# MDR1986VE9x register map
Vendor: Milandr; Series: ARMCM3; File version: 2.0
CPU: CM3 r2p1, little endian, no MPU, no FPU, 3 interrupt priority bits
Registers are 32-bit, read-write, reset 0x0 unless marked. A register's access mark holds for its fields unless they carry their own. Offsets are from the block's base; [hi:lo] are bit positions.

## MDR_I2C — I2C Controler
Base 0x40050000
0x00 PRL — BitRate Div[7:0] of HCLK
  [7:0] PRL — Div[7:0] of HCLK
0x04 PRH — BitRate Div[15:8] of HCLK
  [7:0] PRH — Div[15:8] of HCLK
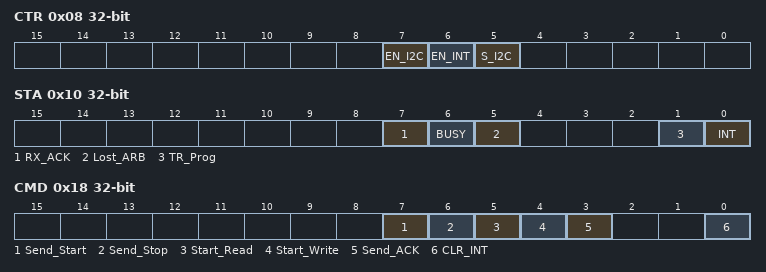
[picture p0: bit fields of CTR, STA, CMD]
0x08 CTR — Control Register
  [7] EN_I2C — Enable
    0=Off (Disabled); 1=On (Enabled)
  [6] EN_INT — Enable IRQ
    0=Off (Disabled); 1=On (Enabled)
  [5] S_I2C — Speed range of I2C
    0=less_400KHz (BitRate is less 400KHz); 1=less_1MHz (BitRate is less 1MHz)
0x0C RXD — Received Data
  [7:0] DATA — Received Byte
0x10 STA — Status register
  [7] RX_ACK — ACK Status
    0=Ok (Acknowledge received); 1=No Acknowledge received
  [6] BUSY — Line Busy
    0=Bus_Free (Stop received); 1=Bus_Busy (Start received)
  [5] Lost_ARB — Lost arbitrage
    0=Ok (Normal operation); 1=Collision detected
  [1] TR_Prog — Transfering status
    0=Completed (Transfering is completed); 1=Transfering is not completed
  [0] INT — IRQ Event Flag
    0=Off (Inactive); 1=On (Active)
0x14 TXD — Data to Send
  [7:0] DATA — Send Byte
0x18 CMD — Command Register
  [7] Send_Start — Send Start command
    0=Inactive state; 1=Send Start command
  [6] Send_Stop — Send Stop command
    0=Inactive state; 1=Send Stop command
  [5] Start_Read — Start Reading transfer
    0=Inactive state; 1=Start reading
  [4] Start_Write — Start Writing transfer
    0=Inactive state; 1=Start_Write (Start writing)
  [3] Send_ACK — Send ACK command
    0=Inactive state; 1=Send Ack command
  [0] CLR_INT — Clear IRQ Event
    0=Inactive state; 1=Clear IRQ flag

## MDR_Power — Power Detector
Base 0x40058000
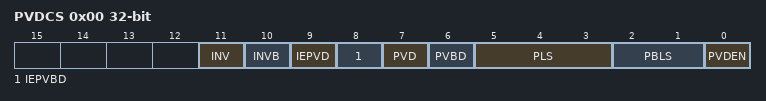
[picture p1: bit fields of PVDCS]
0x00 PVDCS — Control-Status register
  [11] INV — PVD event on BUcc lt PBLS
    0=Off (Disabled); 1=On (Enabled)
  [10] INVB — PVBD event on BUcc lt PBLS
    0=Off (Disabled); 1=On (Enabled)
  [9] IEPVD — Enable IRQ by PVD event
    0=Off (Disabled); 1=On (Enabled)
  [8] IEPVBD — Enable IRQ by PVBD event
    0=Off (Disabled); 1=On (Enabled)
  [7] PVD — Event on Ucc gt PLS
    0=Inactive (No Event); 1=Active (Event is active)
  [6] PVBD — Event on BUcc gt PBLS
    0=Inactive (No Event); 1=Active (Event is active)
  [5:3] PLS — Ucc compare level
    0=2v0 (Level of 2.0 volts); 1=2v2 (Level of 2.2 volts); 2=2v4 (Level of 2.4 volts); 3=2v6 (Level of 2.6 volts); 4=2v8 (Level of 2.8 volts); 5=3v0 (Level of 3.0 volts); 6=3v2 (Level of 3.2 volts); 7=3v4 (Level of 3.4 volts)
  [2:1] PBLS — BUcc compare level
    0=1v8 (Level of 1.8 volts); 1=2v2 (Level of 2.2 volts); 2=2v6 (Level of 2.6 volts); 3=3v0 (Level of 3.0 volts)
  [0] PVDEN — PVD Enable
    0=Off (Disabled); 1=On (Enabled)
0x04 ResReg ro reset not defined — Reserved register
  [31:0] Value — blank

## MDR_WWDT — Window Watchdog Timer
Base 0x40060000
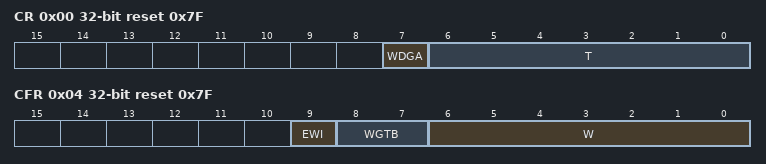
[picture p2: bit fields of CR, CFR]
0x00 CR reset 0x7F — WWDT Control register
  [7] WDGA — Enable
    0=Off (Disabled); 1=On (Enabled)
  [6:0] T — Counter
0x04 CFR reset 0x7F — WWDT Config register
  [9] EWI — Early Window Interrupt
    0=Off (Disabled IRQ on T=0x40); 1=On (Enabled IRQ on T=0x40)
  [8:7] WGTB — Clock Divider
    0=div1 (CLK = LSI/4096/1); 1=div2 (CLK = LSI/4096/2); 2=div4 (CLK = LSI/4096/4); 3=div8 (CLK = LSI/4096/8)
  [6:0] W — Window value
0x08 SR — WWDT Status register
  [0] EWIF — Early Window Flag
    0=Off (Event Off); 1=Onn (Event On)

## MDR_IWDT — Independent Watchdog Timer
Base 0x40068000
0x00 KR wo — Key register
  [15:0] KEY — Enable, start and reload control
0x04 PR — Clock Prescaler register
  [2:0] PR — Prescaler Register
    0=div4 (LSI div 4); 1=div8 (LSI div 8); 2=div16 (LSI div 16); 3=div32 (LSI div 32); 4=div64 (LSI div 64); 5=div128 (LSI div 128); 6=div256 (LSI div 256); 7=div256_1 (LSI div 256)
0x08 RLR reset 0xFFF — Reload Period Register
  [11:0] PRL — Timer Period Value
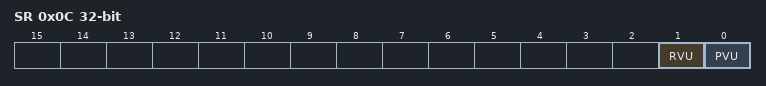
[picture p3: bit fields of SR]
0x0C SR ro — Status Regster
  [1] RVU — PRL busy
    0=Ready (PRL ready for write); 1=Busy (PRL busy)
  [0] PVU — PR busy
    0=Ready (PR ready for write); 1=Busy (PR busy)
